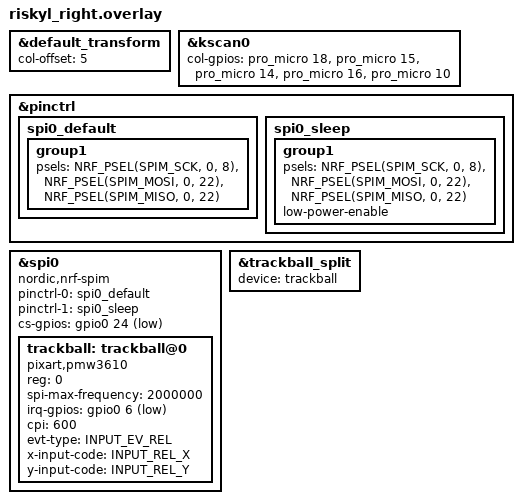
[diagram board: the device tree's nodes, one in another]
/*
 * Copyright (c) 2020 Pete Johanson
 *
 * SPDX-License-Identifier: MIT
 */

#include "riskyl.dtsi"
#include <zephyr/dt-bindings/input/input-event-codes.h>

&default_transform {
    col-offset = <5>;
};
&kscan0 {
    col-gpios
            =
             <&pro_micro 18 GPIO_ACTIVE_HIGH>
            , <&pro_micro 15 GPIO_ACTIVE_HIGH>
            , <&pro_micro 14 GPIO_ACTIVE_HIGH>
            , <&pro_micro 16 GPIO_ACTIVE_HIGH>
            , <&pro_micro 10 GPIO_ACTIVE_HIGH>
            ;
};

&pinctrl {
    spi0_default: spi0_default {
        group1 {
            psels = <NRF_PSEL(SPIM_SCK, 0, 8)>,
                <NRF_PSEL(SPIM_MOSI, 0, 22)>,
                <NRF_PSEL(SPIM_MISO, 0, 22)>;
        };
    };

    spi0_sleep: spi0_sleep {
        group1 {
            psels = <NRF_PSEL(SPIM_SCK, 0, 8)>,
                <NRF_PSEL(SPIM_MOSI, 0, 22)>,
                <NRF_PSEL(SPIM_MISO, 0, 22)>;
            low-power-enable;
        };
    };
};

&spi0 {
    status = "okay";
    compatible = "nordic,nrf-spim";
    pinctrl-0 = <&spi0_default>;
    pinctrl-1 = <&spi0_sleep>;
    pinctrl-names = "default", "sleep";
    cs-gpios = <&gpio0 24 GPIO_ACTIVE_LOW>;

    trackball: trackball@0 {
        status = "okay";
        compatible = "pixart,pmw3610";
        reg = <0>;
        spi-max-frequency = <2000000>;
        irq-gpios = <&gpio0 6 (GPIO_ACTIVE_LOW | GPIO_PULL_UP)>;
        cpi = <600>;
        evt-type = <INPUT_EV_REL>;
        x-input-code = <INPUT_REL_X>;
        y-input-code = <INPUT_REL_Y>;
    };
};

// Overrides for the input-split child node
&trackball_split {
    device = <&trackball>;
};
